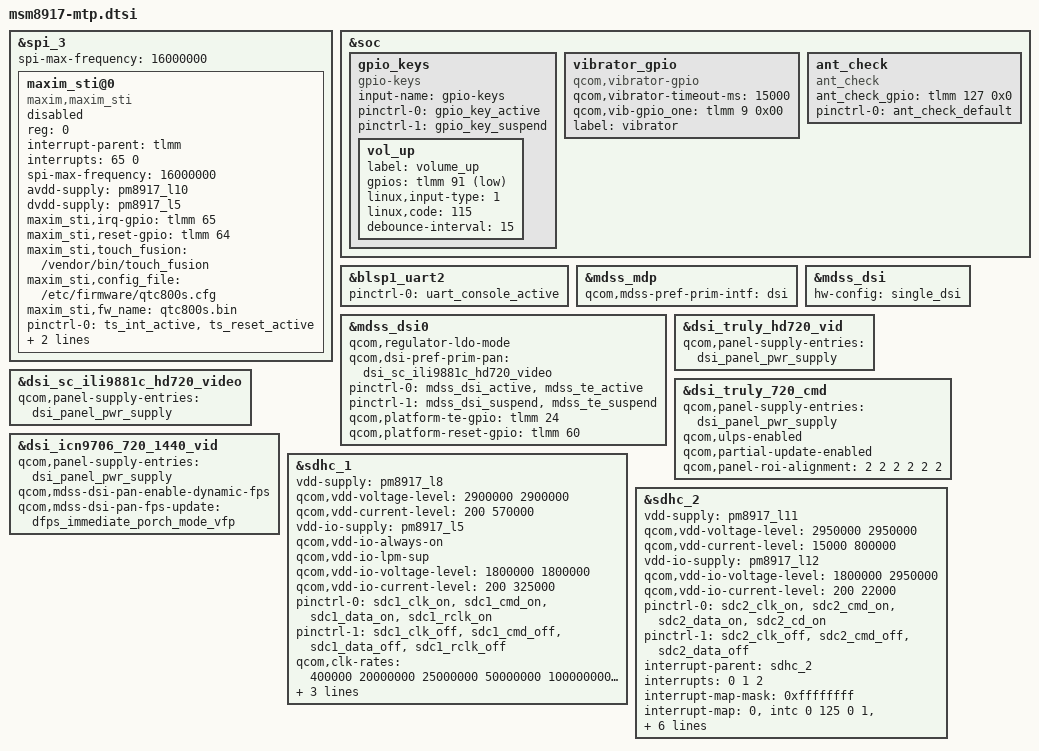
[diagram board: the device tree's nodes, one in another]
/*
 * Copyright (c) 2015-2017, The Linux Foundation. All rights reserved.
 * Copyright (C) 2018 XiaoMi, Inc.
 *
 * This program is free software; you can redistribute it and/or modify
 * it under the terms of the GNU General Public License version 2 and
 * only version 2 as published by the Free Software Foundation.
 *
 * This program is distributed in the hope that it will be useful,
 * but WITHOUT ANY WARRANTY; without even the implied warranty of
 * MERCHANTABILITY or FITNESS FOR A PARTICULAR PURPOSE.  See the
 * GNU General Public License for more details.
 */

#include "msm8917-pinctrl.dtsi"
#include "msm8917-camera-sensor-mtp.dtsi"

&spi_3 { /* BLSP1 QUP3 */
	spi-max-frequency = <16000000>;
	maxim_sti@0 {
		status = "disabled";
		compatible = "maxim,maxim_sti";
		reg = <0>;
		interrupt-parent = <&tlmm>;
		interrupts = <65 0>;
		spi-max-frequency = <16000000>;
		avdd-supply = <&pm8917_l10>;
		dvdd-supply = <&pm8917_l5>;
		maxim_sti,irq-gpio = <&tlmm 65 0x00>;
		maxim_sti,reset-gpio = <&tlmm 64 0x00>;
		maxim_sti,touch_fusion = "/vendor/bin/touch_fusion";
		maxim_sti,config_file = "/etc/firmware/qtc800s.cfg";
		maxim_sti,fw_name = "qtc800s.bin";
		pinctrl-names = "pmx_ts_active","pmx_ts_suspend",
			"pmx_ts_release";
		pinctrl-0 = <&ts_int_active &ts_reset_active>;
		pinctrl-1 = <&ts_int_suspend &ts_reset_suspend>;
		pinctrl-2 = <&ts_release>;
	};
};

&soc {
	gpio_keys {
		compatible = "gpio-keys";
		input-name = "gpio-keys";
		pinctrl-names = "tlmm_gpio_key_active","tlmm_gpio_key_suspend";
		pinctrl-0 = <&gpio_key_active>;
		pinctrl-1 = <&gpio_key_suspend>;

		vol_up {
			label = "volume_up";
			gpios = <&tlmm 91 0x1>;
			linux,input-type = <1>;
			linux,code = <115>;
			debounce-interval = <15>;
		};
	};

	vibrator_gpio {
		compatible = "qcom,vibrator-gpio";
		qcom,vibrator-timeout-ms = <15000>;
		qcom,vib-gpio_one = <&tlmm 9 0x00>;
		label = "vibrator";
	};

	ant_check {
		compatible = "ant_check";
	    ant_check_gpio = <&tlmm 127 0x0>;
		pinctrl-names = "default";
		pinctrl-0 = <&ant_check_default>;
	};
};

&blsp1_uart2 {
	status = "ok";
	pinctrl-names = "default";
	pinctrl-0 = <&uart_console_active>;
};

#include "msm8937-mdss-panels.dtsi"

&mdss_mdp {
	qcom,mdss-pref-prim-intf = "dsi";
};

&mdss_dsi {
	hw-config = "single_dsi";
};

&mdss_dsi0 {
	qcom,regulator-ldo-mode;
	qcom,dsi-pref-prim-pan = <&dsi_sc_ili9881c_hd720_video>;
	pinctrl-names = "mdss_default", "mdss_sleep";
	pinctrl-0 = <&mdss_dsi_active &mdss_te_active>;
	pinctrl-1 = <&mdss_dsi_suspend &mdss_te_suspend>;

	qcom,platform-te-gpio = <&tlmm 24 0>;
	qcom,platform-reset-gpio = <&tlmm 60 0>;
};

&dsi_truly_hd720_vid {
	qcom,panel-supply-entries = <&dsi_panel_pwr_supply>;
};
&dsi_sc_ili9881c_hd720_video{
	qcom,panel-supply-entries = <&dsi_panel_pwr_supply>;
};

&dsi_truly_720_cmd {
	qcom,panel-supply-entries = <&dsi_panel_pwr_supply>;
	qcom,ulps-enabled;
	qcom,partial-update-enabled;
	qcom,panel-roi-alignment = <2 2 2 2 2 2>;
};

&dsi_icn9706_720_1440_vid {
	qcom,panel-supply-entries = <&dsi_panel_pwr_supply>;
	qcom,mdss-dsi-pan-enable-dynamic-fps;
	qcom,mdss-dsi-pan-fps-update = "dfps_immediate_porch_mode_vfp";
};

&sdhc_1 {
	/* device core power supply */
	vdd-supply = <&pm8917_l8>;
	qcom,vdd-voltage-level = <2900000 2900000>;
	qcom,vdd-current-level = <200 570000>;

	/* device communication power supply */
	vdd-io-supply = <&pm8917_l5>;
	qcom,vdd-io-always-on;
	qcom,vdd-io-lpm-sup;
	qcom,vdd-io-voltage-level = <1800000 1800000>;
	qcom,vdd-io-current-level = <200 325000>;

	pinctrl-names = "active", "sleep";
	pinctrl-0 = <&sdc1_clk_on &sdc1_cmd_on &sdc1_data_on &sdc1_rclk_on>;
	pinctrl-1 = <&sdc1_clk_off &sdc1_cmd_off &sdc1_data_off &sdc1_rclk_off>;

	qcom,clk-rates = <400000 20000000 25000000 50000000 100000000 192000000
								384000000>;
	qcom,nonremovable;
	qcom,bus-speed-mode = "HS400_1p8v", "HS200_1p8v", "DDR_1p8v";

	status = "ok";
};

&sdhc_2 {
	/* device core power supply */
	vdd-supply = <&pm8917_l11>;
	qcom,vdd-voltage-level = <2950000 2950000>;
	qcom,vdd-current-level = <15000 800000>;

	/* device communication power supply */
	vdd-io-supply = <&pm8917_l12>;
	qcom,vdd-io-voltage-level = <1800000 2950000>;
	qcom,vdd-io-current-level = <200 22000>;

	pinctrl-names = "active", "sleep";
	pinctrl-0 = <&sdc2_clk_on &sdc2_cmd_on &sdc2_data_on &sdc2_cd_on>;
	pinctrl-1 = <&sdc2_clk_off &sdc2_cmd_off &sdc2_data_off>;

	#address-cells = <0>;
	interrupt-parent = <&sdhc_2>;
	interrupts = <0 1 2>;
	#interrupt-cells = <1>;
	interrupt-map-mask = <0xffffffff>;
	interrupt-map = <0 &intc 0 125 0
		1 &intc 0 221 0
		2 &tlmm 67 0>;
	interrupt-names = "hc_irq", "pwr_irq", "status_irq";
	cd-gpios = <&tlmm 67 0x0>;

	qcom,clk-rates = <400000 20000000 25000000 50000000 100000000
								200000000>;
	qcom,bus-speed-mode = "SDR12", "SDR25", "SDR50", "DDR50", "SDR104";

	status = "ok";
};
